AUTOSAR XML (schema 4-0-3)
package /PATAC/MSM/ComponentTypes
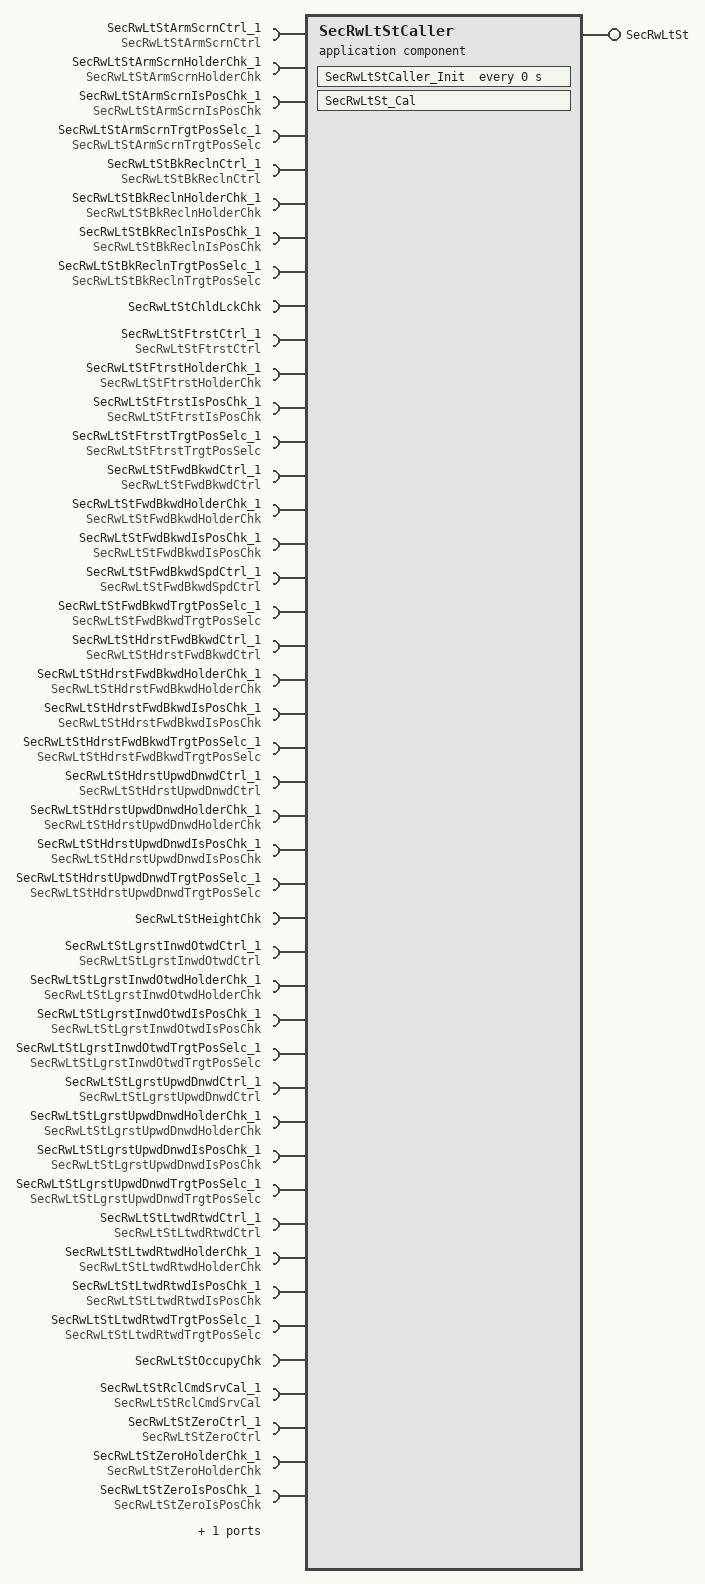
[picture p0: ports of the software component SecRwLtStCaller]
  application sw component type SecRwLtStCaller
    provide port SecRwLtSt: server-com-spec{operation=SecRwLtSt/Cal, queue-length=1}, provided-interface=SecRwLtSt
    45 x require port:
      SecRwLtStArmScrnCtrl_1: client-com-spec=SecRwLtStArmScrnCtrl/Cal, required-interface=SecRwLtStArmScrnCtrl
      SecRwLtStArmScrnHolderChk_1: client-com-spec=SecRwLtStArmScrnHolderChk/Cal, required-interface=SecRwLtStArmScrnHolderChk
      SecRwLtStArmScrnIsPosChk_1: client-com-spec=SecRwLtStArmScrnIsPosChk/Cal, required-interface=SecRwLtStArmScrnIsPosChk
      SecRwLtStArmScrnTrgtPosSelc_1: client-com-spec=SecRwLtStArmScrnTrgtPosSelc/Cal, required-interface=SecRwLtStArmScrnTrgtPosSelc
      SecRwLtStBkReclnCtrl_1: client-com-spec=SecRwLtStBkReclnCtrl/Cal, required-interface=SecRwLtStBkReclnCtrl
      SecRwLtStBkReclnHolderChk_1: client-com-spec=SecRwLtStBkReclnHolderChk/Cal, required-interface=SecRwLtStBkReclnHolderChk
      SecRwLtStBkReclnIsPosChk_1: client-com-spec=SecRwLtStBkReclnIsPosChk/Cal, required-interface=SecRwLtStBkReclnIsPosChk
      SecRwLtStBkReclnTrgtPosSelc_1: client-com-spec=SecRwLtStBkReclnTrgtPosSelc/Cal, required-interface=SecRwLtStBkReclnTrgtPosSelc
      SecRwLtStChldLckChk: client-com-spec=SecRwLtStChldLckChk/Cal, required-interface=SecRwLtStChldLckChk
      SecRwLtStFtrstCtrl_1: client-com-spec=SecRwLtStFtrstCtrl/Cal, required-interface=SecRwLtStFtrstCtrl
      SecRwLtStFtrstHolderChk_1: client-com-spec=SecRwLtStFtrstHolderChk/Cal, required-interface=SecRwLtStFtrstHolderChk
      SecRwLtStFtrstIsPosChk_1: client-com-spec=SecRwLtStFtrstIsPosChk/Cal, required-interface=SecRwLtStFtrstIsPosChk
      SecRwLtStFtrstTrgtPosSelc_1: client-com-spec=SecRwLtStFtrstTrgtPosSelc/Cal, required-interface=SecRwLtStFtrstTrgtPosSelc
      SecRwLtStFwdBkwdCtrl_1: client-com-spec=SecRwLtStFwdBkwdCtrl/Cal, required-interface=SecRwLtStFwdBkwdCtrl
      SecRwLtStFwdBkwdHolderChk_1: client-com-spec=SecRwLtStFwdBkwdHolderChk/Cal, required-interface=SecRwLtStFwdBkwdHolderChk
      SecRwLtStFwdBkwdIsPosChk_1: client-com-spec=SecRwLtStFwdBkwdIsPosChk/Cal, required-interface=SecRwLtStFwdBkwdIsPosChk
      SecRwLtStFwdBkwdSpdCtrl_1: client-com-spec=SecRwLtStFwdBkwdSpdCtrl/Cal, required-interface=SecRwLtStFwdBkwdSpdCtrl
      SecRwLtStFwdBkwdTrgtPosSelc_1: client-com-spec=SecRwLtStFwdBkwdTrgtPosSelc/Cal, required-interface=SecRwLtStFwdBkwdTrgtPosSelc
      SecRwLtStHdrstFwdBkwdCtrl_1: client-com-spec=SecRwLtStHdrstFwdBkwdCtrl/Cal, required-interface=SecRwLtStHdrstFwdBkwdCtrl
      SecRwLtStHdrstFwdBkwdHolderChk_1: client-com-spec=SecRwLtStHdrstFwdBkwdHolderChk/Cal, required-interface=SecRwLtStHdrstFwdBkwdHolderChk
      SecRwLtStHdrstFwdBkwdIsPosChk_1: client-com-spec=SecRwLtStHdrstFwdBkwdIsPosChk/Cal, required-interface=SecRwLtStHdrstFwdBkwdIsPosChk
      SecRwLtStHdrstFwdBkwdTrgtPosSelc_1: client-com-spec=SecRwLtStHdrstFwdBkwdTrgtPosSelc/Cal, required-interface=SecRwLtStHdrstFwdBkwdTrgtPosSelc
      SecRwLtStHdrstUpwdDnwdCtrl_1: client-com-spec=SecRwLtStHdrstUpwdDnwdCtrl/Cal, required-interface=SecRwLtStHdrstUpwdDnwdCtrl
      SecRwLtStHdrstUpwdDnwdHolderChk_1: client-com-spec=SecRwLtStHdrstUpwdDnwdHolderChk/Cal, required-interface=SecRwLtStHdrstUpwdDnwdHolderChk
      SecRwLtStHdrstUpwdDnwdIsPosChk_1: client-com-spec=SecRwLtStHdrstUpwdDnwdIsPosChk/Cal, required-interface=SecRwLtStHdrstUpwdDnwdIsPosChk
      SecRwLtStHdrstUpwdDnwdTrgtPosSelc_1: client-com-spec=SecRwLtStHdrstUpwdDnwdTrgtPosSelc/Cal, required-interface=SecRwLtStHdrstUpwdDnwdTrgtPosSelc
      SecRwLtStHeightChk: client-com-spec=SecRwLtStHeightChk/Cal, required-interface=SecRwLtStHeightChk
      SecRwLtStLgrstInwdOtwdCtrl_1: client-com-spec=SecRwLtStLgrstInwdOtwdCtrl/Cal, required-interface=SecRwLtStLgrstInwdOtwdCtrl
      SecRwLtStLgrstInwdOtwdHolderChk_1: client-com-spec=SecRwLtStLgrstInwdOtwdHolderChk/Cal, required-interface=SecRwLtStLgrstInwdOtwdHolderChk
      SecRwLtStLgrstInwdOtwdIsPosChk_1: client-com-spec=SecRwLtStLgrstInwdOtwdIsPosChk/Cal, required-interface=SecRwLtStLgrstInwdOtwdIsPosChk
      SecRwLtStLgrstInwdOtwdTrgtPosSelc_1: client-com-spec=SecRwLtStLgrstInwdOtwdTrgtPosSelc/Cal, required-interface=SecRwLtStLgrstInwdOtwdTrgtPosSelc
      SecRwLtStLgrstUpwdDnwdCtrl_1: client-com-spec=SecRwLtStLgrstUpwdDnwdCtrl/Cal, required-interface=SecRwLtStLgrstUpwdDnwdCtrl
      SecRwLtStLgrstUpwdDnwdHolderChk_1: client-com-spec=SecRwLtStLgrstUpwdDnwdHolderChk/Cal, required-interface=SecRwLtStLgrstUpwdDnwdHolderChk
      SecRwLtStLgrstUpwdDnwdIsPosChk_1: client-com-spec=SecRwLtStLgrstUpwdDnwdIsPosChk/Cal, required-interface=SecRwLtStLgrstUpwdDnwdIsPosChk
      SecRwLtStLgrstUpwdDnwdTrgtPosSelc_1: client-com-spec=SecRwLtStLgrstUpwdDnwdTrgtPosSelc/Cal, required-interface=SecRwLtStLgrstUpwdDnwdTrgtPosSelc
      SecRwLtStLtwdRtwdCtrl_1: client-com-spec=SecRwLtStLtwdRtwdCtrl/Cal, required-interface=SecRwLtStLtwdRtwdCtrl
      SecRwLtStLtwdRtwdHolderChk_1: client-com-spec=SecRwLtStLtwdRtwdHolderChk/Cal, required-interface=SecRwLtStLtwdRtwdHolderChk
      SecRwLtStLtwdRtwdIsPosChk_1: client-com-spec=SecRwLtStLtwdRtwdIsPosChk/Cal, required-interface=SecRwLtStLtwdRtwdIsPosChk
      SecRwLtStLtwdRtwdTrgtPosSelc_1: client-com-spec=SecRwLtStLtwdRtwdTrgtPosSelc/Cal, required-interface=SecRwLtStLtwdRtwdTrgtPosSelc
      SecRwLtStOccupyChk: client-com-spec=SecRwLtStOccupyChk/Cal, required-interface=SecRwLtStOccupyChk
      SecRwLtStRclCmdSrvCal_1: client-com-spec=SecRwLtStRclCmdSrvCal/Cal, required-interface=SecRwLtStRclCmdSrvCal
      SecRwLtStZeroCtrl_1: client-com-spec=SecRwLtStZeroCtrl/Cal, required-interface=SecRwLtStZeroCtrl
      SecRwLtStZeroHolderChk_1: client-com-spec=SecRwLtStZeroHolderChk/Cal, required-interface=SecRwLtStZeroHolderChk
      SecRwLtStZeroIsPosChk_1: client-com-spec=SecRwLtStZeroIsPosChk/Cal, required-interface=SecRwLtStZeroIsPosChk
      SecRwLtStZeroTrgtPosSelc_1: client-com-spec=SecRwLtStZeroTrgtPosSelc/Cal, required-interface=SecRwLtStZeroTrgtPosSelc
    behavior SecRwLtStCaller_InternalBehavior
      operation invoked event OIT_SecRwLtSt_Cal_SecRwLtSt_Cal: start-on-event=SecRwLtSt_Cal, operation=SecRwLtSt.Cal
      timing event SecRwLtStCaller_InitEvent: start-on-event=SecRwLtStCaller_Init, period=0
      runnable SecRwLtSt_Cal
        45 x sync call, all with timeout=0:
          SC_SecRwLtStArmScrnCtrl_1_Cal: operation=SecRwLtStArmScrnCtrl_1.Cal
          SC_SecRwLtStArmScrnHolderChk_1_Cal: operation=SecRwLtStArmScrnHolderChk_1.Cal
          SC_SecRwLtStArmScrnIsPosChk_1_Cal: operation=SecRwLtStArmScrnIsPosChk_1.Cal
          SC_SecRwLtStArmScrnTrgtPosSelc_1_Cal: operation=SecRwLtStArmScrnTrgtPosSelc_1.Cal
          SC_SecRwLtStBkReclnCtrl_1_Cal: operation=SecRwLtStBkReclnCtrl_1.Cal
          SC_SecRwLtStBkReclnHolderChk_1_Cal: operation=SecRwLtStBkReclnHolderChk_1.Cal
          SC_SecRwLtStBkReclnIsPosChk_1_Cal: operation=SecRwLtStBkReclnIsPosChk_1.Cal
          SC_SecRwLtStBkReclnTrgtPosSelc_1_Cal: operation=SecRwLtStBkReclnTrgtPosSelc_1.Cal
          SC_SecRwLtStChldLckChk_Cal: operation=SecRwLtStChldLckChk.Cal
          SC_SecRwLtStFtrstCtrl_1_Cal: operation=SecRwLtStFtrstCtrl_1.Cal
          SC_SecRwLtStFtrstHolderChk_1_Cal: operation=SecRwLtStFtrstHolderChk_1.Cal
          SC_SecRwLtStFtrstIsPosChk_1_Cal: operation=SecRwLtStFtrstIsPosChk_1.Cal
          SC_SecRwLtStFtrstTrgtPosSelc_1_Cal: operation=SecRwLtStFtrstTrgtPosSelc_1.Cal
          SC_SecRwLtStFwdBkwdCtrl_1_Cal: operation=SecRwLtStFwdBkwdCtrl_1.Cal
          SC_SecRwLtStFwdBkwdHolderChk_1_Cal: operation=SecRwLtStFwdBkwdHolderChk_1.Cal
          SC_SecRwLtStFwdBkwdIsPosChk_1_Cal: operation=SecRwLtStFwdBkwdIsPosChk_1.Cal
          SC_SecRwLtStFwdBkwdSpdCtrl_1_Cal: operation=SecRwLtStFwdBkwdSpdCtrl_1.Cal
          SC_SecRwLtStFwdBkwdTrgtPosSelc_1_Cal: operation=SecRwLtStFwdBkwdTrgtPosSelc_1.Cal
          SC_SecRwLtStHdrstFwdBkwdCtrl_1_Cal: operation=SecRwLtStHdrstFwdBkwdCtrl_1.Cal
          SC_SecRwLtStHdrstFwdBkwdHolderChk_1_Cal: operation=SecRwLtStHdrstFwdBkwdHolderChk_1.Cal
          SC_SecRwLtStHdrstFwdBkwdIsPosChk_1_Cal: operation=SecRwLtStHdrstFwdBkwdIsPosChk_1.Cal
          SC_SecRwLtStHdrstFwdBkwdTrgtPosSelc_1_Cal: operation=SecRwLtStHdrstFwdBkwdTrgtPosSelc_1.Cal
          SC_SecRwLtStHdrstUpwdDnwdCtrl_1_Cal: operation=SecRwLtStHdrstUpwdDnwdCtrl_1.Cal
          SC_SecRwLtStHdrstUpwdDnwdHolderChk_1_Cal: operation=SecRwLtStHdrstUpwdDnwdHolderChk_1.Cal
          SC_SecRwLtStHdrstUpwdDnwdIsPosChk_1_Cal: operation=SecRwLtStHdrstUpwdDnwdIsPosChk_1.Cal
          SC_SecRwLtStHdrstUpwdDnwdTrgtPosSelc_1_Cal: operation=SecRwLtStHdrstUpwdDnwdTrgtPosSelc_1.Cal
          SC_SecRwLtStHeightChk_Cal: operation=SecRwLtStHeightChk.Cal
          SC_SecRwLtStLgrstInwdOtwdCtrl_1_Cal: operation=SecRwLtStLgrstInwdOtwdCtrl_1.Cal
          SC_SecRwLtStLgrstInwdOtwdHolderChk_1_Cal: operation=SecRwLtStLgrstInwdOtwdHolderChk_1.Cal
          SC_SecRwLtStLgrstInwdOtwdIsPosChk_1_Cal: operation=SecRwLtStLgrstInwdOtwdIsPosChk_1.Cal
          SC_SecRwLtStLgrstInwdOtwdTrgtPosSelc_1_Cal: operation=SecRwLtStLgrstInwdOtwdTrgtPosSelc_1.Cal
          SC_SecRwLtStLgrstUpwdDnwdCtrl_1_Cal: operation=SecRwLtStLgrstUpwdDnwdCtrl_1.Cal
          SC_SecRwLtStLgrstUpwdDnwdHolderChk_1_Cal: operation=SecRwLtStLgrstUpwdDnwdHolderChk_1.Cal
          SC_SecRwLtStLgrstUpwdDnwdIsPosChk_1_Cal: operation=SecRwLtStLgrstUpwdDnwdIsPosChk_1.Cal
          SC_SecRwLtStLgrstUpwdDnwdTrgtPosSelc_1_Cal: operation=SecRwLtStLgrstUpwdDnwdTrgtPosSelc_1.Cal
          SC_SecRwLtStLtwdRtwdCtrl_1_Cal: operation=SecRwLtStLtwdRtwdCtrl_1.Cal
          SC_SecRwLtStLtwdRtwdHolderChk_1_Cal: operation=SecRwLtStLtwdRtwdHolderChk_1.Cal
          SC_SecRwLtStLtwdRtwdIsPosChk_1_Cal: operation=SecRwLtStLtwdRtwdIsPosChk_1.Cal
          SC_SecRwLtStLtwdRtwdTrgtPosSelc_1_Cal: operation=SecRwLtStLtwdRtwdTrgtPosSelc_1.Cal
          SC_SecRwLtStOccupyChk_Cal: operation=SecRwLtStOccupyChk.Cal
          SC_SecRwLtStRclCmdSrvCal_1_Cal: operation=SecRwLtStRclCmdSrvCal_1.Cal
          SC_SecRwLtStZeroCtrl_1_Cal: operation=SecRwLtStZeroCtrl_1.Cal
          SC_SecRwLtStZeroHolderChk_1_Cal: operation=SecRwLtStZeroHolderChk_1.Cal
          SC_SecRwLtStZeroIsPosChk_1_Cal: operation=SecRwLtStZeroIsPosChk_1.Cal
          SC_SecRwLtStZeroTrgtPosSelc_1_Cal: operation=SecRwLtStZeroTrgtPosSelc_1.Cal
      runnable SecRwLtStCaller_Init
  swc implementation SecRwLtStCaller_Implementation: behavior=SecRwLtStCaller_InternalBehavior
    code-descriptors:
      code Default: artifact-descriptors=autosar-engineering-object={short-label=Default, category=SWSRC}
package /PATAC/MSM/ModeAdjust/PortInterface
  46 x client server interface:
    SecRwLtSt
      operation Cal
    SecRwLtStArmScrnCtrl
      operation Cal
    SecRwLtStArmScrnHolderChk
      operation Cal
    SecRwLtStArmScrnIsPosChk
      operation Cal
    SecRwLtStArmScrnTrgtPosSelc
      operation Cal
    SecRwLtStBkReclnCtrl
      operation Cal
    SecRwLtStBkReclnHolderChk
      operation Cal
    SecRwLtStBkReclnIsPosChk
      operation Cal
    SecRwLtStBkReclnTrgtPosSelc
      operation Cal
    SecRwLtStChldLckChk
      operation Cal
    SecRwLtStFtrstCtrl
      operation Cal
    SecRwLtStFtrstHolderChk
      operation Cal
    SecRwLtStFtrstIsPosChk
      operation Cal
    SecRwLtStFtrstTrgtPosSelc
      operation Cal
    SecRwLtStFwdBkwdCtrl
      operation Cal
    SecRwLtStFwdBkwdHolderChk
      operation Cal
    SecRwLtStFwdBkwdIsPosChk
      operation Cal
    SecRwLtStFwdBkwdSpdCtrl
      operation Cal
    SecRwLtStFwdBkwdTrgtPosSelc
      operation Cal
    SecRwLtStHdrstFwdBkwdCtrl
      operation Cal
    SecRwLtStHdrstFwdBkwdHolderChk
      operation Cal
    SecRwLtStHdrstFwdBkwdIsPosChk
      operation Cal
    SecRwLtStHdrstFwdBkwdTrgtPosSelc
      operation Cal
    SecRwLtStHdrstUpwdDnwdCtrl
      operation Cal
    SecRwLtStHdrstUpwdDnwdHolderChk
      operation Cal
    SecRwLtStHdrstUpwdDnwdIsPosChk
      operation Cal
    SecRwLtStHdrstUpwdDnwdTrgtPosSelc
      operation Cal
    SecRwLtStHeightChk
      operation Cal
    SecRwLtStLgrstInwdOtwdCtrl
      operation Cal
    SecRwLtStLgrstInwdOtwdHolderChk
      operation Cal
    SecRwLtStLgrstInwdOtwdIsPosChk
      operation Cal
    SecRwLtStLgrstInwdOtwdTrgtPosSelc
      operation Cal
    SecRwLtStLgrstUpwdDnwdCtrl
      operation Cal
    SecRwLtStLgrstUpwdDnwdHolderChk
      operation Cal
    SecRwLtStLgrstUpwdDnwdIsPosChk
      operation Cal
    SecRwLtStLgrstUpwdDnwdTrgtPosSelc
      operation Cal
    SecRwLtStLtwdRtwdCtrl
      operation Cal
    SecRwLtStLtwdRtwdHolderChk
      operation Cal
    SecRwLtStLtwdRtwdIsPosChk
      operation Cal
    SecRwLtStLtwdRtwdTrgtPosSelc
      operation Cal
    SecRwLtStOccupyChk
      operation Cal
    SecRwLtStRclCmdSrvCal
      operation Cal
    SecRwLtStZeroCtrl
      operation Cal
    SecRwLtStZeroHolderChk
      operation Cal
    SecRwLtStZeroIsPosChk
      operation Cal
    SecRwLtStZeroTrgtPosSelc
      operation Cal
